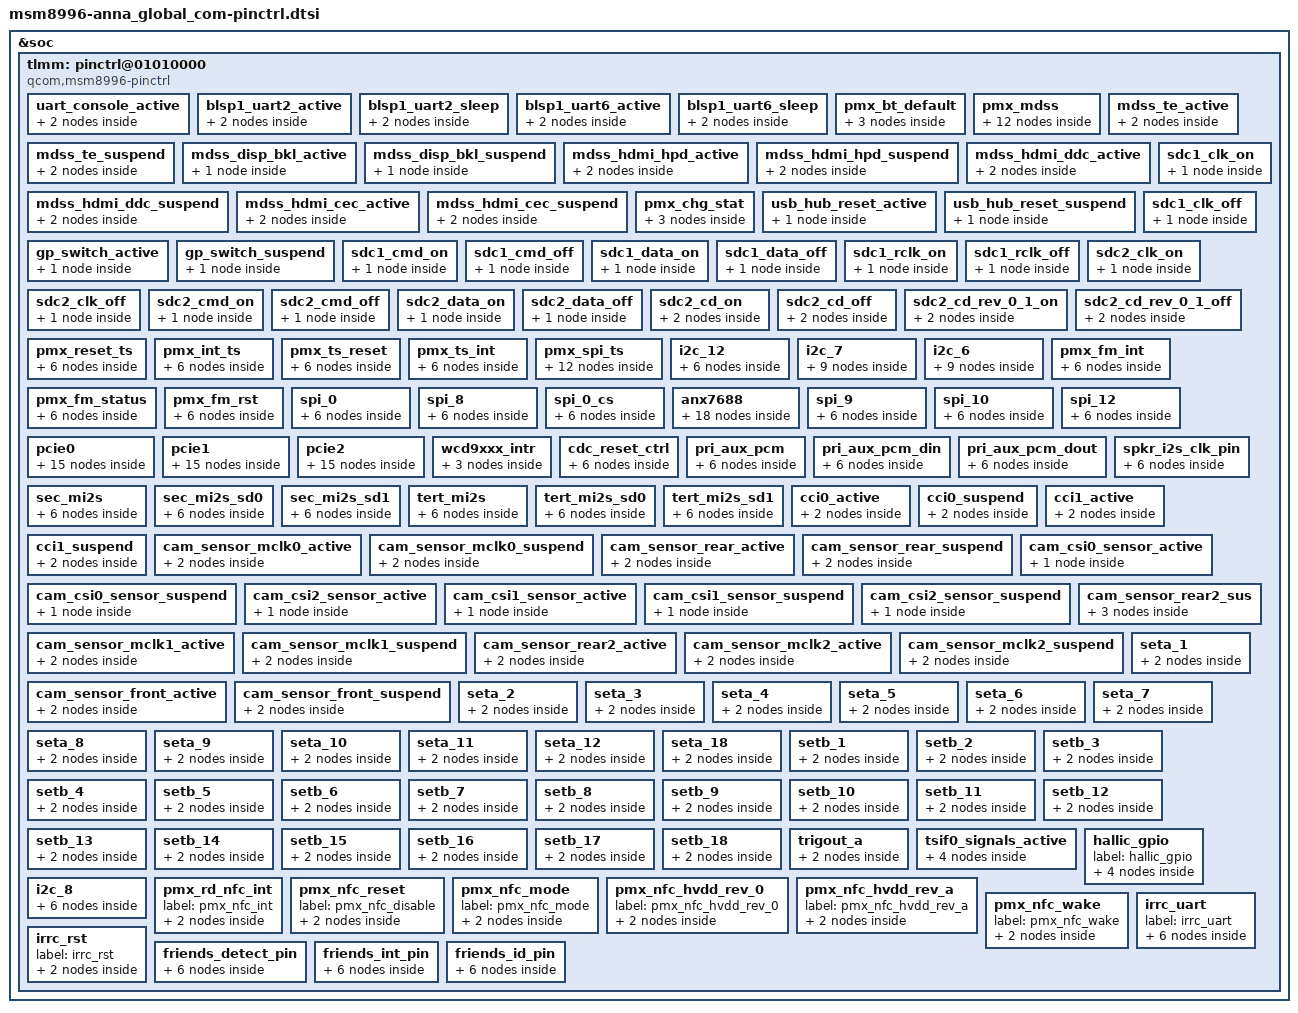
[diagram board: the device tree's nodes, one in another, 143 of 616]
/* Copyright (c) 2014-2015, The Linux Foundation. All rights reserved.
 *
 * This program is free software; you can redistribute it and/or modify
 * it under the terms of the GNU General Public License version 2 and
 * only version 2 as published by the Free Software Foundation.
 *
 * This program is distributed in the hope that it will be useful,
 * but WITHOUT ANY WARRANTY; without even the implied warranty of
 * MERCHANTABILITY or FITNESS FOR A PARTICULAR PURPOSE.  See the
 * GNU General Public License for more details.
 */

&soc {
	tlmm: pinctrl@01010000 {
		compatible = "qcom,msm8996-pinctrl";
		reg = <0x01010000 0x300000>;
		interrupts = <0 208 0>;
		gpio-controller;
		#gpio-cells = <2>;
		interrupt-controller;
		#interrupt-cells = <2>;

		uart_console_active: uart_console_active {
			mux {
				pins = "gpio4", "gpio5";
				function = "blsp_uart8";
			};

			config {
				pins = "gpio4", "gpio5";
				drive-strength = <6>;
				bias-disable;
			};
		};

		blsp1_uart2_active: blsp1_uart2_active {
			mux {
				pins = "gpio41", "gpio42", "gpio43", "gpio44";
				function = "blsp_uart2";
			};

			config {
				pins = "gpio41", "gpio42", "gpio43", "gpio44";
				drive-strength = <2>;
				bias-disable;
			};
		};

		blsp1_uart2_sleep: blsp1_uart2_sleep {
			mux {
				pins = "gpio41", "gpio42", "gpio43", "gpio44";
				function = "gpio";
			};

			config {
				pins = "gpio41", "gpio42", "gpio43", "gpio44";
				drive-strength = <2>;
				bias-disable;
			};
		};
//[ANNA_ISDBT_BRINGUP_S] : duplicated
/*
		blsp1_uart3_active: blsp1_uart3_active {
			mux {
				pins = "gpio45", "gpio46", "gpio47", "gpio48";
				function = "blsp_uart3";
			};

			config {
				pins = "gpio45", "gpio46", "gpio47", "gpio48";
				drive-strength = <2>;
				bias-disable;
			};
		};

		blsp1_uart3_sleep: blsp1_uart3_sleep {
			mux {
				pins = "gpio45", "gpio46", "gpio47", "gpio48";
				function = "gpio";
			};

			config {
				pins = "gpio45", "gpio46", "gpio47", "gpio48";
				drive-strength = <2>;
				bias-disable;
			};
		};
*/
//[ANNA_ISDBT_BRINGUP_E]
		blsp1_uart6_active: blsp1_uart6_active {
			mux {
				pins = "gpio25", "gpio26", "gpio27", "gpio28";
				function = "blsp_uart6";
			};

			config {
				pins = "gpio25", "gpio26", "gpio27", "gpio28";
				drive-strength = <2>;
				bias-disable;
			};
		};

		blsp1_uart6_sleep: blsp1_uart6_sleep {
			mux {
				pins = "gpio25", "gpio26", "gpio27", "gpio28";
				function = "gpio";
			};

			config {
				pins = "gpio25", "gpio26", "gpio27", "gpio28";
				drive-strength = <2>;
				bias-disable;
			};
		};

//[H1_BT_BRINGUP_S]
                /* gpio pin mux for bluetooth enable pin */
//[ANNA_ISDBT_BRINGUP_S] : duplicated
/*
		i2c_3 {
			i2c_3_active: i2c_3_active {
				mux {
					pins = "gpio47", "gpio48";
					function = "blsp_i2c3";
				};

				config {
					pins = "gpio47", "gpio48";
					drive-strength = <2>;
					bias-disable;
				};
			};

			i2c_3_sleep: i2c_3_sleep {
				mux {
					pins = "gpio47", "gpio48";
					function = "blsp_i2c3";
				};

				config {
					pins = "gpio47", "gpio48";
					drive-strength = <2>;
					bias-pull-up;
				};
			};
		};
*/		
//[ANNA_ISDBT_BRINGUP_E]
		/* gpio pin mux for bluetooth host wake pin */
                pmx_bt_default {
			bt_default: bt_default {
				mux {
					pins = "gpio24", "gpio92";
					function = "gpio";
				};

	    			config {
	    				pins = "gpio24", "gpio92";
	    				drive-strength = <2>;
	    				bias-disable = <0>;
	    			};
	                };
		};
//[H1_BT_BRINGUP_E]


		pmx_mdss: pmx_mdss {
			mdss_dsi_active: mdss_dsi_active {
				mux {
					pins = "gpio8";
					function = "gpio";
				};

				pmx_mdss {
					pins = "gpio8";
					drive-strength = <8>; /* 8 mA */
					bias-disable = <0>; /* no pull */
					output-high;
				};
			};
			mdss_dsi_suspend: mdss_dsi_suspend {
				mux {
					pins = "gpio8";
					function = "gpio";
				};

				config {
					pins = "gpio8";
					drive-strength = <2>; /* 2 mA */
					bias-pull-down; /* pull down */
				};
			};

			mdss_dsi_active3: mdss_dsi_active3 {
				mux {
					pins = "gpio121";
					function = "gpio";
				};

				pmx_mdss {
					pins = "gpio121";
					drive-strength = <2>; /* 2 mA */
					bias-pull-down;  /* pull down */
				};
			};
			mdss_dsi_suspend3: mdss_dsi_suspend3 {
				mux {
					pins = "gpio121";
					function = "gpio";
				};

				config {
					pins = "gpio121";
					drive-strength = <2>; /* 2 mA */
					bias-bus-hold;
				};
			};
		};

		mdss_te_active: mdss_te_active {
			mux {
				pins = "gpio10";
				function = "mdp_vsync";
			};
			config {
				pins = "gpio10";
				drive-strength = <2>; /* 8 mA */
				bias-pull-down; /* pull down*/
			};
		};


		mdss_te_suspend: mdss_te_suspend {
			mux {
				pins = "gpio10";
				function = "mdp_vsync";
			};
			config {
				pins = "gpio10";
				drive-strength = <2>; /* 2 mA */
				bias-pull-down; /* pull down */
			};
		};

		mdss_disp_bkl_active: mdss_disp_bkl_active {
			config {
				pins = "gpio135";
				drive-strength = <8>; /* 8 mA */
				bias-disable; /* no pull */
				output-high;
			};
		};

		mdss_disp_bkl_suspend: mdss_disp_bkl_suspend {
			config {
				pins = "gpio135";
				drive-strength = <2>; /* 2 mA */
				bias-pull-down; /* pull down */
			};
		};

		mdss_hdmi_hpd_active: mdss_hdmi_hpd_active {
			mux {
				pins = "gpio34";
				function = "hdmi_hot";
			};

			config {
				pins = "gpio34";
				bias-pull-down;
				drive-strength = <16>;
			};
		};

		mdss_hdmi_hpd_suspend: mdss_hdmi_hpd_suspend {
			mux {
				pins = "gpio34";
				function = "hdmi_hot";
			};

			config {
				pins = "gpio34";
				bias-bus-hold;
				drive-strength = <2>;
			};
		};

		mdss_hdmi_ddc_active: mdss_hdmi_ddc_active {
			mux {
				pins = "gpio32", "gpio33";
				function = "hdmi_ddc";
			};

			config {
				pins = "gpio32", "gpio33";
				drive-strength = <2>;
				bias-pull-up;
			};
		};

		mdss_hdmi_ddc_suspend: mdss_hdmi_ddc_suspend {
			mux {
				pins = "gpio32", "gpio33";
				function = "hdmi_ddc";
			};

			config {
				pins = "gpio32", "gpio33";
				drive-strength = <2>;
				bias-disable;
			};
		};

		mdss_hdmi_cec_active: mdss_hdmi_cec_active {
			mux {
				pins = "gpio31";
				function = "hdmi_cec";
			};

			config {
				pins = "gpio31";
				drive-strength = <2>;
				bias-pull-up;
			};
		};

		mdss_hdmi_cec_suspend: mdss_hdmi_cec_suspend {
			mux {
				pins = "gpio31";
				function = "hdmi_cec";
			};

			config {
				pins = "gpio31";
				drive-strength = <2>;
				bias-disable;
			};
		};

		/* gpio pin mux for back-up battery charging status pin */
		pmx_chg_stat {
			chg_stat_active: chg_stat_active {
				mux {
					pins = "gpio45";
					function = "gpio";
				};
				config {
					pins = "gpio45";
					drive-strength = <2>;
					bias-pull-up;
				};
			};
		};

		usb_hub_reset_active: usb_hub_reset_active {
			usb_hub_reset_active {
				pins = "gpio103";
				drive-strength = <8>; /* 8 mA */
				bias-pull-up;  /* pull up */
				output-high;
			};
		};

		usb_hub_reset_suspend: usb_hub_reset_suspend {
			usb_hub_reset_suspend {
				pins = "gpio103";
				drive-strength = <2>; /* 2 mA */
				bias-disable= <0>; /* no pull */
			};
		};


		gp_switch_active: gp_switch_active {
			gp_switch_active {
				pins = "gpio127";
				drive-strength = <8>; /* 8 mA */
				bias-pull-up;  /* pull up */
				output-low;
			};
		};

		gp_switch_suspend: gp_switch_suspend {
			gp_switch_suspend {
				pins = "gpio127";
				drive-strength = <2>; /* 2 mA */
				bias-disable= <0>; /* no pull */
			};
		};


		sdc1_clk_on: sdc1_clk_on {
			config {
				pins = "sdc1_clk";
				bias-disable;		/* NO pull */
				drive-strength = <16>;	/* 16 MA */
			};
		};

		sdc1_clk_off: sdc1_clk_off {
			config {
				pins = "sdc1_clk";
				bias-disable;		/* NO pull */
				drive-strength = <2>;	/* 2 MA */
			};
		};

		sdc1_cmd_on: sdc1_cmd_on {
			config {
				pins = "sdc1_cmd";
				bias-pull-up;		/* pull up */
				drive-strength = <10>;	/* 10 MA */
			};
		};

		sdc1_cmd_off: sdc1_cmd_off {
			config {
				pins = "sdc1_cmd";
				num-grp-pins = <1>;
				bias-pull-up;		/* pull up */
				drive-strength = <2>;	/* 2 MA */
			};
		};

		sdc1_data_on: sdc1_data_on {
			config {
				pins = "sdc1_data";
				bias-pull-up;		/* pull up */
				drive-strength = <10>;	/* 10 MA */
			};
		};

		sdc1_data_off: sdc1_data_off {
			config {
				pins = "sdc1_data";
				bias-pull-up;		/* pull up */
				drive-strength = <2>;	/* 2 MA */
			};
		};

		sdc1_rclk_on: sdc1_rclk_on {
			config {
				pins = "sdc1_rclk";
				bias-pull-down;		/* pull down */
			};
		};

		sdc1_rclk_off: sdc1_rclk_off {
			config {
				pins = "sdc1_rclk";
				bias-pull-down;		/* pull down */
			};
		};

		sdc2_clk_on: sdc2_clk_on {
			config {
				pins = "sdc2_clk";
				bias-disable;		/* NO pull */
				drive-strength = <16>;	/* 16 MA */
			};
		};

		sdc2_clk_off: sdc2_clk_off {
			config {
				pins = "sdc2_clk";
				bias-disable;		/* NO pull */
				drive-strength = <2>;	/* 2 MA */
			};
		};

		sdc2_cmd_on: sdc2_cmd_on {
			config {
				pins = "sdc2_cmd";
				bias-pull-up;		/* pull up */
				drive-strength = <10>;	/* 10 MA */
			};
		};

		sdc2_cmd_off: sdc2_cmd_off {
			config {
				pins = "sdc2_cmd";
				bias-pull-up;		/* pull up */
				drive-strength = <2>;	/* 2 MA */
			};
		};

		sdc2_data_on: sdc2_data_on {
			config {
				pins = "sdc2_data";
				bias-pull-up;		/* pull up */
				drive-strength = <10>;	/* 10 MA */
			};
		};

		sdc2_data_off: sdc2_data_off {
			config {
				pins = "sdc2_data";
				bias-pull-up;		/* pull up */
				drive-strength = <2>;	/* 2 MA */
			};
		};

		sdc2_cd_on: sdc2_cd_on {
			mux {
				pins = "gpio79";
				function = "gpio";
			};

			config {
				pins = "gpio79";
				bias-pull-up;		/* pull up */
				drive-strength = <16>;	/* 16 MA */
			};
		};

		sdc2_cd_off: sdc2_cd_off {
			mux {
				pins = "gpio79";
				function = "gpio";
			};

			config {
				pins = "gpio79";
				bias-disable;		/* no pull */
				drive-strength = <2>;	/* 2 MA */
			};
		};

        sdc2_cd_rev_0_1_on: sdc2_cd_rev_0_1_on {
            mux {
                pins = "gpio112";
                function = "gpio";
            };

            config {
                pins = "gpio112";
                bias-pull-up;
                drive_strength = <16>;
            };
        };

        sdc2_cd_rev_0_1_off: sdc2_cd_rev_0_1_off {
            mux {
                pins = "gpio112";
                function = "gpio";
            };

            config {
                pins = "gpio112";
                bias-pull-up;
                drive_strength = <2>;
            };
        };

		pmx_reset_ts {
			reset_active_ts: reset_active_ts {
				mux {
					pins = "gpio89";
					function = "gpio";
				};
				config {
					pins = "gpio89";
					drive-strength = <6>;
					bias-pull-up;
				};
			};

			reset_suspend_ts: reset_suspend_ts {
				mux {
					pins = "gpio89";
					function = "gpio";
				};
				config {
					pins = "gpio89";
					drive-strength = <6>;
					bias-pull-down;
				};
			};
		};

		pmx_int_ts {
			int_active_ts: int_active_ts {
				mux {
					pins = "gpio125";
					function = "gpio";
				};
				config {
					pins = "gpio125";
					drive-strength = <2>;
					bias-disable;
				};
			};

			int_suspend_ts: int_suspend_ts {
				mux {
					pins = "gpio125";
					function = "gpio";
				};
				config {
					pins = "gpio125";
					drive-strength = <2>;
					bias-disable;
				};
			};
		};

		pmx_ts_reset {
			ts_reset_active: ts_reset_active {
				mux {
					pins = "gpio89";
					function = "gpio";
				};
				config {
					pins = "gpio89";
					drive-strength = <6>;
					bias-pull-up;
				};
			};

			ts_reset_suspend: ts_reset_suspend {
				mux {
					pins = "gpio89";
					function = "gpio";
				};
				config {
					pins = "gpio89";
					drive-strength = <6>;
					bias-pull-down;
				};
			};
		};

		pmx_ts_int {
			ts_int_active: ts_int_active {
				mux {
					pins = "gpio125";
					function = "gpio";
				};
				config {
					pins = "gpio125";
					drive-strength = <2>;
					bias-pull-up;
				};
			};

			ts_int_suspend: ts_int_suspend {
				mux {
					pins = "gpio125";
					function = "gpio";
				};
				config {
					pins = "gpio125";
					drive-strength = <2>;
					bias-disable;
				};
			};
		};

		pmx_spi_ts: pmx_spi_ts {
			spi_ts_active: spi_ts_active {
			/* TOUCH MOSI, MISO */
				mux {
					pins = "gpio85", "gpio86";
					function = "blsp_spi12";
				};
				config {
					pins = "gpio85", "gpio86";
					drive-strength = <8>; /* 8MA */
					bias-pull-up;
				};
			};

			spi_ts_suspend: spi_ts_suspend {
			/* TOUCH MOSI, MISO */
				mux {
					pins = "gpio85", "gpio86";
					function = "blsp_spi12";
				};
				config {
					pins = "gpio85", "gpio86";
					drive-strength = <2>; /* 2MA */
					bias-disable; /* No PULL */
				};
			};

			spi_ts_cs_active: spi_ts_cs_active {
				mux {
					pins = "gpio87", "gpio88";
					function = "blsp_spi12";
				};
				config {
					pins = "gpio87", "gpio88";
					drive-strength = <8>;
					bias-pull-up;
				};
			};

			spi_ts_cs_suspend: spi_ts_cs_suspend {
				mux {
					pins = "gpio87", "gpio88";
					function = "blsp_spi12";
				};
				config {
					pins = "gpio87", "gpio88";
					drive-strength = <2>;
					bias-disable; /* No PULL */
				};
			};
		};

		i2c_12 {
			i2c_12_active: i2c_12_active {
				mux {
					pins = "gpio87", "gpio88";
					function = "blsp_i2c12";
				};

				config {
					pins = "gpio87", "gpio88";
					drive-strength = <2>;
					bias-disable;
				};
			};

			i2c_12_sleep: i2c_12_sleep {
				mux {
					pins = "gpio87", "gpio88";
					function = "blsp_i2c12";
				};

				config {
					pins = "gpio87", "gpio88";
					drive-strength = <2>;
					bias-pull-up;
				};
			};

		};

		i2c_7 {
			i2c_7_default: i2c_7_default {
				mux {
					pins = "gpio55", "gpio56";
					function = "blsp_i2c7";
				};

				config {
					pins = "gpio55", "gpio56";
					drive-strength = <2>;
					bias-disable;
				};
			};

			i2c_7_active: i2c_7_active {
				mux {
					pins = "gpio55", "gpio56";
					function = "blsp_i2c7";
				};

				config {
					pins = "gpio55", "gpio56";
					drive-strength = <2>;
					bias-disable;
				};
			};

			i2c_7_sleep: i2c_7_sleep {
				mux {
					pins = "gpio55", "gpio56";
					function = "blsp_i2c7";
				};

				config {
					pins = "gpio55", "gpio56";
					drive-strength = <2>;
					bias-pull-up;
				};
			};

		};

		i2c_6 {
			i2c_6_default: i2c_6_default {
				mux {
					pins = "gpio27", "gpio28";
					function = "blsp_i2c6";
				};

				config {
					pins = "gpio27", "gpio28";
					drive-strength = <2>;
					bias-disable;
				};
			};

			i2c_6_active: i2c_6_active {
				mux {
					pins = "gpio27", "gpio28";
					function = "blsp_i2c6";
				};

				config {
					pins = "gpio27", "gpio28";
					drive-strength = <2>;
					bias-disable;
				};
			};


			i2c_6_sleep: i2c_6_sleep {
				mux {
					pins = "gpio27", "gpio28";
					function = "blsp_i2c6";
				};

				config {
					pins = "gpio27", "gpio28";
					drive-strength = <2>;
					bias-pull-up;
				};
			};

		};

		pmx_fm_int {
			fm_int_active: fm_int_active {
				mux {
					pins = "gpio38";
					function = "gpio";
				};

				config {
					pins = "gpio38";
					drive-strength = <16>;
					bias-pull-up;
				};
			};

		fm_int_suspend: fm_int_suspend {
				mux {
					pins = "gpio38";
					function = "gpio";
				};

				config {
					pins = "gpio38";
					drive-strength = <16>;
					bias-pull-up;
				};
			};
		};

		pmx_fm_status {
			fm_status_int_active: fm_status_int_active {
				mux {
					pins = "gpio78";
					function = "gpio";
				};

				config {
					pins = "gpio78";
					drive-strength = <16>;
					bias-pull-up;
				};
			};

			fm_status_int_suspend: fm_status_int_suspend {
				mux {
					pins = "gpio78";
					function = "gpio";
				};

				config {
					pins = "gpio78";
					drive-strength = <16>;
					bias-pull-up;
				};
			};
		};

		pmx_fm_rst {
			fm_rst_active: fm_rst_active {
				mux {
					pins = "gpio39";
					function = "gpio";
				};

				config {
					pins = "gpio39";
					drive-strength = <16>;
					bias-pull-down;
				};
			};

			fm_rst_suspend: fm_rst_suspend {
				mux {
					pins = "gpio39";
					function = "gpio";
				};

				config {
					pins = "gpio39";
					drive-strength = <16>;
					bias-pull-down;
				};
			};
		};

		spi_0 {
			spi_0_active: spi_0_active {
				mux {
					pins = "gpio0", "gpio1",
						"gpio2", "gpio3";
					function = "blsp_spi1";
				};

				config {
					pins = "gpio0", "gpio1",
						"gpio2", "gpio3";
					drive-strength = <6>;
					bias-disable;
				};
			};

			spi_0_sleep: spi_0_sleep {
				mux {
					pins = "gpio0", "gpio1",
						"gpio2", "gpio3";
					function = "blsp_spi1";
				};

				config {
					pins = "gpio0", "gpio1",
						"gpio2", "gpio3";
					drive-strength = <6>;
					bias-disable;
				};
			};
		};

		spi_8 {
			spi_8_active: spi_8_active {
				mux {
					pins = "gpio49", "gpio50",
					        "gpio51", "gpio52";
					function = "blsp_spi9";
				};

				config {
					pins = "gpio49", "gpio50",
					        "gpio51", "gpio52";
					drive-strength = <6>;
					bias-disable;
				};
			};

			spi_8_sleep: spi_8_sleep {
				mux {
					pins = "gpio49", "gpio50",
						"gpio51", "gpio52";
					function = "blsp_spi9";
				};

				config {
					pins = "gpio49", "gpio50",
						"gpio51", "gpio52";
					drive-strength = <6>;
					bias-disable;
				};
			};
		};

		spi_0_cs {
			spi_0_cs_active: spi_0_cs_active {
				mux {
					pins = "gpio24", "gpio90";
					function = "blsp1_spi";
				};

				config {
					pins = "gpio24", "gpio90";
					drive-strength = <6>;
					bias-pull-up;
				};
			};

			spi_0_cs_sleep: spi_0_cs_sleep {
				mux {
					pins = "gpio24", "gpio90";
					function = "blsp1_spi";
				};

				config {
					pins = "gpio24", "gpio90";
					drive-strength = <6>;
					bias-pull-up;
				};
			};
		};

		anx7688 {
			anx7688_cable_det_active: anx7688_cable_det_active {
				mux {
					pins = "gpio131";
					function = "gpio";
				};

				config {
					pins = "gpio131";
					driver-strength = <8>;
					bias-bus-hold;
				};
			};

			anx7688_cable_det_sleep: anx7688_cable_det_sleep {
				mux {
					pins = "gpio131";
					function = "gpio";
				};

				config {
					pins = "gpio131";
					driver-strength = <2>;
					bias-bus-hold;
				};
			};

			anx7688_alt_active: anx7688_alt_active {
				mux {
					pins = "gpio46";
					function = "gpio";
				};

				config {
					pins = "gpio46";
					driver-strength = <8>;
					bias-pull-up;
				};
			};

			anx7688_alt_sleep: anx7688_alt_sleep {
				mux {
					pins = "gpio46";
					function = "gpio";
				};

				config {
					pins = "gpio46";
					driver-strength = <2>;
					bias-pull-up;
				};
			};
                        anx7688_hpd_active: anx7688_hpd_active {
                                mux {
                                        pins = "gpio34";
                                        function = "gpio";
                                };

                                config {
                                        pins = "gpio34";
                                        driver-strength = <8>;
                                        bias-disable;
                                };
                        };

                        anx7688_hpd_sleep: anx7688_hpd_sleep {
                                mux {
                                        pins = "gpio34";
                                        function = "gpio";
                                };

                                config {
                                        pins = "gpio34";
                                        driver-strength = <8>;
                                        bias-disable;
                                };
                        };

		};

		spi_9 {
			spi_9_active: spi_9_active {
				mux {
					pins = "gpio49", "gpio50", "gpio51",
								"gpio52";
					function = "blsp_spi9";
				};

				config {
					pins = "gpio49", "gpio50", "gpio51",
								"gpio52";
					drive-strength = <6>;
					bias-disable;
				};
			};

			spi_9_sleep: spi_9_sleep {
				mux {
					pins = "gpio49", "gpio50", "gpio51",
								"gpio52";
					function = "blsp_spi9";
				};

				config {
					pins = "gpio49", "gpio50", "gpio51",
								"gpio52";
					drive-strength = <6>;
					bias-disable;
				};
			};
		};

		spi_10 {
			spi_10_active: spi_10_active {
				mux {
					pins = "gpio8", "gpio9", "gpio10",
								"gpio11";
					function = "blsp_spi10";
				};

				config {
					pins = "gpio8", "gpio9", "gpio10",
								"gpio11";
					drive-strength = <6>;
					bias-disable;
				};
			};

			spi_10_sleep: spi_10_sleep {
				mux {
					pins = "gpio8", "gpio9", "gpio10",
								"gpio11";
					function = "blsp_spi10";
				};

				config {
					pins = "gpio8", "gpio9", "gpio10",
								"gpio11";
					drive-strength = <6>;
					bias-disable;
				};
			};
		};

		spi_12 {
			spi_12_active: spi_12_active {
				mux {
					pins = "gpio85", "gpio86", "gpio87",
								"gpio88";
					function = "blsp_spi12";
				};

				config {
					pins = "gpio85", "gpio86", "gpio87",
								"gpio88";
					drive-strength = <6>;
					bias-disable;
				};
			};

			spi_12_sleep: spi_12_sleep {
				mux {
					pins = "gpio85", "gpio86", "gpio87",
								"gpio88";
					function = "blsp_spi12";
				};

				config {
					pins = "gpio85", "gpio86", "gpio87",
								"gpio88";
					drive-strength = <6>;
					bias-disable;
				};
			};
		};

		pcie0 {
			pcie0_clkreq_default: pcie0_clkreq_default {
				mux {
					pins = "gpio36";
					function = "pci_e0";
				};

				config {
					pins = "gpio36";
					drive-strength = <2>;
					bias-pull-up;
				};
			};

			pcie0_perst_default: pcie0_perst_default {
				mux {
					pins = "gpio35";
					function = "gpio";
				};

				config {
					pins = "gpio35";
					drive-strength = <2>;
					bias-pull-down;
				};
			};

			pcie0_wake_default: pcie0_wake_default {
				mux {
					pins = "gpio37";
					function = "gpio";
				};

				config {
					pins = "gpio37";
					drive-strength = <2>;
					bias-pull-up;
				};
			};

			pcie0_clkreq_sleep: pcie0_clkreq_sleep {
				mux {
					pins = "gpio36";
					function = "gpio";
				};

				config {
					pins = "gpio36";
					drive-strength = <2>;
					bias-disable;
				};
			};

			pcie0_wake_sleep: pcie0_wake_sleep {
				mux {
					pins = "gpio37";
					function = "gpio";
				};

				config {
					pins = "gpio37";
					drive-strength = <2>;
					bias-disable;
				};
			};
		};

		pcie1 {
			pcie1_clkreq_default: pcie1_clkreq_default {
				mux {
					pins = "gpio131";
					function = "pci_e0";
				};

				config {
					pins = "gpio131";
					drive-strength = <2>;
					bias-pull-up;
				};
			};

			pcie1_perst_default: pcie1_perst_default {
				mux {
					pins = "gpio130";
					function = "gpio";
				};

				config {
					pins = "gpio130";
					drive-strength = <2>;
					bias-pull-down;
				};
			};

			pcie1_wake_default: pcie1_wake_default {
				mux {
					pins = "gpio132";
					function = "gpio";
				};

				config {
					pins = "gpio132";
					drive-strength = <2>;
					bias-pull-up;
				};
			};

			pcie1_clkreq_sleep: pcie1_clkreq_sleep {
				mux {
					pins = "gpio131";
					function = "gpio";
				};

				config {
					pins = "gpio131";
					drive-strength = <2>;
					bias-disable;
				};
			};

			pcie1_wake_sleep: pcie1_wake_sleep {
				mux {
					pins = "gpio132";
					function = "gpio";
				};

				config {
					pins = "gpio132";
					drive-strength = <2>;
					bias-disable;
				};
			};
		};

		pcie2 {
			pcie2_clkreq_default: pcie2_clkreq_default {
				mux {
					pins = "gpio115";
					function = "pci_e2";
				};

				config {
					pins = "gpio115";
					drive-strength = <2>;
					bias-pull-up;
				};
			};

			pcie2_perst_default: pcie2_perst_default {
				mux {
					pins = "gpio114";
					function = "gpio";
				};

				config {
					pins = "gpio114";
					drive-strength = <2>;
					bias-pull-down;
				};
			};

			pcie2_wake_default: pcie2_wake_default {
				mux {
					pins = "gpio116";
					function = "gpio";
				};

				config {
					pins = "gpio116";
					drive-strength = <2>;
					bias-pull-down;
				};
			};

			pcie2_clkreq_sleep: pcie2_clkreq_sleep {
				mux {
					pins = "gpio115";
					function = "gpio";
				};

				config {
					pins = "gpio115";
					drive-strength = <2>;
					bias-disable;
				};
			};

			pcie2_wake_sleep: pcie2_wake_sleep {
				mux {
					pins = "gpio116";
					function = "gpio";
				};

				config {
					pins = "gpio116";
					drive-strength = <2>;
					bias-disable;
				};
			};
		};

		wcd9xxx_intr {
			wcd_intr_default: wcd_intr_default{
				mux {
					pins = "gpio54";
					function = "gpio";
				};

				config {
					pins = "gpio54";
					drive-strength = <2>; /* 2 mA */
					bias-pull-down; /* pull down */
					input-enable;
				};
			};
		};

		cdc_reset_ctrl {
			cdc_reset_sleep: cdc_reset_sleep {
				mux {
					pins = "gpio64";
					function = "gpio";
				};
				config {
					pins = "gpio64";
					drive-strength = <16>;
					bias-disable;
					output-low;
				};
			};
			cdc_reset_active:cdc_reset_active {
				mux {
					pins = "gpio64";
					function = "gpio";
				};
				config {
					pins = "gpio64";
					drive-strength = <16>;
					bias-pull-down;
					output-high;
				};
			};
		};

		pri_aux_pcm {
			pri_aux_pcm_sleep: pri_aux_pcm_sleep {
				mux {
					pins = "gpio65", "gpio66", "gpio67";
					function = "pri_mi2s";
				};

				config {
					pins = "gpio65", "gpio66", "gpio67";
					drive-strength = <2>;   /* 2 mA */
					bias-pull-down;         /* PULL DOWN */
				};
			};
			pri_aux_pcm_active: pri_aux_pcm_active {
				mux {
					pins = "gpio65", "gpio66", "gpio67";
					function = "pri_mi2s";
				};

				config {
					pins = "gpio65", "gpio66", "gpio67";
					drive-strength = <8>;   /* 8 mA */
					bias-disable;           /* NO PULL */
					output-high;
				};
			};
		};

		pri_aux_pcm_din {
			pri_aux_pcm_din_sleep: pri_aux_pcm_din_sleep {
				mux {
					pins = "gpio68";
					function = "pri_mi2s";
				};

				config {
					pins = "gpio68";
					drive-strength = <2>;   /* 2 mA */
					bias-pull-down;         /* PULL DOWN */
				};
			};
			pri_aux_pcm_din_active: pri_aux_pcm_din_active {
				mux {
					pins = "gpio68";
					function = "pri_mi2s";
				};

				config {
					pins = "gpio68";
					drive-strength = <8>;   /* 8 mA */
					bias-disable;           /* NO PULL */
				};
			};
		};

		pri_aux_pcm_dout {
			pri_aux_pcm_dout_sleep: pri_aux_pcm_dout_sleep {
				mux {
					pins = "gpio68";
					function = "pri_mi2s";
				};

				config {
					pins = "gpio68";
					drive-strength = <2>;   /* 2 mA */
					bias-pull-down;         /* PULL DOWN */
				};
			};
			pri_aux_pcm_dout_active: pri_aux_pcm_dout_active {
				mux {
					pins = "gpio68";
					function = "pri_mi2s";
				};

				config {
					pins = "gpio68";
					drive-strength = <8>;   /* 8 mA */
					bias-disable;           /* NO PULL */
				};
			};
		};

		spkr_i2s_clk_pin {
			spkr_i2s_clk_sleep: spkr_i2s_clk_sleep {
				mux {
					pins = "gpio143";
					function = "spkr_i2s";
				};

				config {
					pins = "gpio143";
					drive-strength = <2>; /* 2 mA */
					bias-pull-down;       /* PULL DOWN */
				};
			};
			spkr_i2s_clk_active: spkr_i2s_clk_active {
				mux {
					pins = "gpio143";
					function = "spkr_i2s";
				};

				config {
					pins = "gpio143";
					drive-strength = <8>; /* 8 mA */
					bias-disable;         /* NO PULL */
				};
			};
		};

    	sec_mi2s {
			sec_mi2s_sleep: sec_mi2s_sleep {
				mux {
					pins = "gpio80", "gpio81";
					function = "sec_mi2s";
				};
				config {
					pins = "gpio80", "gpio81";
					drive-strength = <2>;   /* 2 mA */
					bias-pull-down;         /* PULL DOWN */
				};
			};
			sec_mi2s_active: sec_mi2s_active {
				mux {
					pins = "gpio80", "gpio81";
					function = "sec_mi2s";
				};
				config {
					pins = "gpio80", "gpio81";
					drive-strength = <8>;   /* 8 mA */
					bias-disable;           /* NO PULL */
				};
			};
		};
        
		sec_mi2s_sd0 {
			sec_mi2s_sd0_sleep: sec_mi2s_sd0_sleep {
				mux {
					pins = "gpio82";
					function = "sec_mi2s";
				};
				config {
					pins = "gpio82";
					drive-strength = <2>;   /* 2 mA */
					bias-pull-down;         /* PULL DOWN */
				};
			};
			sec_mi2s_sd0_active: sec_mi2s_sd0_active {
				mux {
					pins = "gpio82";
					function = "sec_mi2s";
				};
				config {
					pins = "gpio82";
					drive-strength = <8>;   /* 8 mA */
					bias-disable;           /* NO PULL */
				};
			};
		};

		sec_mi2s_sd1 {
			sec_mi2s_sd1_sleep: sec_mi2s_sd1_sleep {
				mux {
					pins = "gpio83";
					function = "sec_mi2s";
				};
				config {
					pins = "gpio83";
					drive-strength = <2>;   /* 2 mA */
					bias-pull-down;         /* PULL DOWN */
				};
			};
			sec_mi2s_sd1_active: sec_mi2s_sd1_active {
				mux {
					pins = "gpio83";
					function = "sec_mi2s";
				};
				config {
					pins = "gpio83";
					drive-strength = <8>;   /* 8 mA */
					bias-disable;           /* NO PULL */
				};
			};
		};

		tert_mi2s{
			tert_mi2s_sleep: tert_mi2s_sleep{
				mux {
					pins = "gpio75", "gpio76";
					function = "ter_mi2s";
				};
				config {
					pins = "gpio75", "gpio76";
					drive-strength = <2>;   /* 2 mA */
					bias-pull-down;         /* PULL DOWN */
				};
			};
			tert_mi2s_active: tert_mi2s_active{
				mux {
					pins = "gpio75", "gpio76";
					function = "ter_mi2s";
				};
				config {
					pins = "gpio75", "gpio76";
					drive-strength = <8>;   /* 8 mA */
					bias-disable;           /* NO PULL */
				};
			};
		};

		tert_mi2s_sd0 {
			tert_mi2s_sd0_sleep: tert_mi2s_sd0_sleep {
				mux {
					pins = "gpio77";
					function = "ter_mi2s";
				};
				config {
					pins = "gpio77";
					drive-strength = <2>;   /* 2 mA */
					bias-pull-down;         /* PULL DOWN */
				};
			};
			tert_mi2s_sd0_active: tert_mi2s_sd0_active {
				mux {
					pins = "gpio77";
					function = "ter_mi2s";
				};
				config {
					pins = "gpio77";
					drive-strength = <8>;   /* 8 mA */
					bias-disable;           /* NO PULL */
				};
			};
		};

		tert_mi2s_sd1 {
			tert_mi2s_sd1_sleep: tert_mi2s_sd1_sleep {
				mux {
					pins = "gpio78";
					function = "ter_mi2s";
				};
				config {
					pins = "gpio78";
					drive-strength = <2>;   /* 2 mA */
					bias-pull-down;         /* PULL DOWN */
				};
			};
			tert_mi2s_sd1_active: tert_mi2s_sd1_active {
				mux {
					pins = "gpio78";
					function = "ter_mi2s";
				};
				config {
					pins = "gpio78";
					drive-strength = <8>;   /* 8 mA */
					bias-disable;           /* NO PULL */
				};
			};
		};

		cci0_active: cci0_active {
			mux {
				/* CLK, DATA */
				pins = "gpio17","gpio18"; // Only 2
				function = "cci_i2c";
			};

			config {
				pins = "gpio17","gpio18";
				bias-disable; /* No PULL */
				drive-strength = <2>; /* 2 MA */
			};
		};

		cci0_suspend: cci0_suspend {
			mux {
				/* CLK, DATA */
				pins = "gpio17","gpio18";
				function = "cci_i2c";
			};

			config {
				pins = "gpio17","gpio18";
				bias-disable; /* No PULL */
				drive-strength = <2>; /* 2 MA */
			};
		};

		cci1_active: cci1_active {
			mux {
				/* CLK, DATA */
				pins = "gpio19","gpio20";
				function = "cci_i2c";
			};

			config {
				pins = "gpio19","gpio20";
				bias-disable; /* No PULL */
				drive-strength = <2>; /* 2 MA */
			};
		};

		cci1_suspend: cci1_suspend {
			mux {
				/* CLK, DATA */
				pins = "gpio19","gpio20";
				function = "cci_i2c";
			};

			config {
				pins = "gpio19","gpio20";
				bias-disable; /* No PULL */
				drive-strength = <2>; /* 2 MA */
			};
		};

		cam_sensor_mclk0_active: cam_sensor_mclk0_active {
			/* MCLK0 */
			mux {
				/* CLK, DATA */
				pins = "gpio13";
				function = "cam_mclk";
			};

			config {
				pins = "gpio13";
				bias-disable; /* No PULL */
				drive-strength = <2>; /* 2 MA */
			};
		};

		cam_sensor_mclk0_suspend: cam_sensor_mclk0_suspend {
			/* MCLK0 */
			mux {
				/* CLK, DATA */
				pins = "gpio13";
				function = "cam_mclk";
			};

			config {
				pins = "gpio13";
				bias-pull-down; /* PULL DOWN */
				drive-strength = <2>; /* 2 MA */
			};
		};

		cam_sensor_rear_active: cam_sensor_rear_active {
			/* RESET, STANDBY */
			mux {
				pins = "gpio30";
				function = "gpio";
			};

			config {
				pins = "gpio30"; //,"gpio29";
				bias-disable; /* No PULL */
				drive-strength = <2>; /* 2 MA */
			};
		};

		cam_sensor_rear_suspend: cam_sensor_rear_suspend{
			/* RESET, STANDBY */
			mux {
				pins = "gpio30"; //,"gpio29";
				function = "gpio";
			};

			config {
				pins = "gpio30"; //,"gpio29";
				bias-disable; /* No PULL */
				drive-strength = <2>; /* 2 MA */
			};
		};

		cam_csi0_sensor_active: cam_csi0_sensor_active {
			/* RESET, STANDBY */
			cam_rear_active_cfg {
				pins = "gpio25","gpio26";
				bias-disable; /* No PULL */
				drive-strength = <2>; /* 2 MA */
			};
		};

		cam_csi0_sensor_suspend: cam_csi0_sensor_suspend{
			/* RESET, STANDBY */
			cam_rear_suspend_cfg {
				pins = "gpio25","gpio26";
				bias-disable; /* No PULL */
				drive-strength = <2>; /* 2 MA */
			};
		};

		cam_csi2_sensor_active: cam_csi2_sensor_active {
			/* RESET, STANDBY */
			cam_rear_active_cfg {
				pins = "gpio23","gpio133";
				bias-disable; /* No PULL */
				drive-strength = <2>; /* 2 MA */
			};
		};

		cam_csi1_sensor_active: cam_csi1_sensor_active {
			/* RESET, STANDBY */
			cam_rear_active_cfg {
				pins = "gpio104","gpio98";
				bias-disable; /* No PULL */
				drive-strength = <2>; /* 2 MA */
			};
		};

		cam_csi1_sensor_suspend: cam_csi1_sensor_suspend {
			/* RESET, STANDBY */
			cam_rear_suspend_cfg {
				pins = "gpio104","gpio98";
				bias-disable; /* No PULL */
				drive-strength = <2>; /* 2 MA */
			};
		};

		cam_csi2_sensor_suspend: cam_csi2_sensor_suspend{
			/* RESET, STANDBY */
			cam_rear_suspend_cfg {
				pins = "gpio23","gpio133";
				bias-disable; /* No PULL */
				drive-strength = <2>; /* 2 MA */
			};
		};

		cam_sensor_mclk1_active: cam_sensor_mclk1_active{
			/* MCLK1 */
			mux {
				/* CLK, DATA */
				pins = "gpio14";
				function = "cam_mclk";
			};

			config {
				pins = "gpio14";
				bias-disable; /* No PULL */
				drive-strength = <2>; /* 2 MA */
			};
		};

		cam_sensor_mclk1_suspend: cam_sensor_mclk1_suspend {
			/* MCLK1 */
			mux {
				/* CLK, DATA */
				pins = "gpio14";
				function = "cam_mclk";
			};

			config {
				pins = "gpio14";
				bias-pull-down; /* PULL DOWN */
				drive-strength = <2>; /* 2 MA */
			};
		};

		cam_sensor_rear2_active: cam_sensor_rear2_active {
			/* RESET, STANDBY */
			mux {
				pins = "gpio29"; //"gpio63","gpio62";
				function = "gpio";
			};

			config {
				pins = "gpio29"; //"gpio63","gpio62";
				bias-disable; /* No PULL */
				drive-strength = <2>; /* 2 MA */
			};
		};

		cam_sensor_rear2_sus {
			cam_sensor_rear2_suspend: cam_sensor_rear2_suspend{
				/* RESET, STANDBY */
				mux {
					pins = "gpio29"; //"gpio63","gpio62";
					function = "gpio";
				};

				config {
					pins = "gpio29"; //"gpio63","gpio62";
					bias-disable; /* No PULL */
					drive-strength = <2>; /* 2 MA */
				};
			};
		};

		cam_sensor_mclk2_active: cam_sensor_mclk2_active {
			/* MCLK1 */
			mux {
				/* CLK, DATA */
				pins = "gpio15";
				function = "cam_mclk";
			};

			config {
				pins = "gpio15";
				bias-disable; /* No PULL */
				drive-strength = <2>; /* 2 MA */
			};
		};

		cam_sensor_mclk2_suspend: cam_sensor_mclk2_suspend{
			/* MCLK1 */
			mux {
				/* CLK, DATA */
				pins = "gpio15";
				function = "cam_mclk";
			};

			config {
				pins = "gpio15";
				bias-pull-down; /* PULL DOWN */
				drive-strength = <2>; /* 2 MA */
			};
		};

		cam_sensor_front_active: cam_sensor_front_active{
			/* RESET, STANDBY */
			mux {
				pins = "gpio23";//,"gpio26";
				function = "gpio";
			};

			config {
				pins = "gpio23";//,"gpio26";
				bias-disable; /* No PULL */
				drive-strength = <2>; /* 2 MA */
			};
		};

		cam_sensor_front_suspend: cam_sensor_front_suspend{
			/* RESET, STANDBY */
			mux {
				pins = "gpio23";//,"gpio26";
				function = "gpio";
			};

			config {
				pins = "gpio23";//,"gpio26";
				bias-disable; /* No PULL */
				drive-strength = <2>; /* 2 MA */
			};
		};

		/* CoreSight */
		seta_1: seta_1 {
			mux {
				pins = "gpio27";
				function = "gpio";
			};

			config {
				pins = "gpio27";
				function = "qdss_tracectl_a";
				drive-strength = <16>;
				bias-disable;
			};
		};

		seta_2: seta_2 {
			mux {
				pins = "gpio28";
				function = "qdss_tracectl_a";
			};

			config {
				pins = "gpio28";
				drive-strength = <16>;
				bias-disable;
			};
		};

		seta_3: seta_3 {
			mux {
				pins = "gpio53";
				function = "qdss_tracedata_a";
			};

			config {
				pins = "gpio53";
				drive-strength = <16>;
				bias-disable;
			};
		};

		seta_4: seta_4 {
			mux {
				pins = "gpio54";
				function = "qdss_tracedata_a";
			};

			config {
				pins = "gpio54";
				drive-strength = <16>;
				bias-disable;
			};
		};

		seta_5: seta_5 {
			mux {
				pins = "gpio63";
				function = "qdss_tracedata_a";
			};

			config {
				pins = "gpio63";
				drive-strength = <16>;
				bias-disable;
			};
		};

		seta_6: seta_6 {
			mux {
				pins = "gpio64";
				function = "qdss_tracedata_a";
			};

			config {
				pins = "gpio64";
				drive-strength = <16>;
				bias-disable;
			};
		};

		seta_7: seta_7 {
			mux {
				pins = "gpio65";
				function = "qdss_tracedata_a";
			};

			config {
				pins = "gpio65";
				drive-strength = <16>;
				bias-disable;
			};
		};

		seta_8: seta_8 {
			mux {
				pins = "gpio66";
				function = "qdss_tracedata_a";
			};

			config {
				pins = "gpio66";
				drive-strength = <16>;
				bias-disable;
			};
		};

		seta_9: seta_9 {
			mux {
				pins = "gpio67";
				function = "qdss_tracedata_a";
			};

			config {
				pins = "gpio67";
				drive-strength = <16>;
				bias-disable;
			};
		};

		seta_10: seta_10 {
			mux {
				pins = "gpio74";
				function = "qdss_tracedata_a";
			};

			config {
				pins = "gpio74";
				drive-strength = <16>;
				bias-disable;
			};
		};

		seta_11: seta_11 {
			mux {
				pins = "gpio75";
				function = "qdss_tracedata_a";
			};

			config {
				pins = "gpio75";
				drive-strength = <16>;
				bias-disable;
			};
		};

		seta_12: seta_12 {
			mux {
				pins = "gpio76";
				function = "qdss_tracedata_a";
			};

			config {
				pins = "gpio76";
				drive-strength = <16>;
				bias-disable;
			};
		};
/*
		seta_13: seta_13 {
			mux {
				pins = "gpio77";
				function = "qdss_tracedata_a";
			};

			config {
				pins = "gpio77";
				drive-strength = <16>;
				bias-disable;
			};
		};

		seta_14: seta_14 {
			mux {
				pins = "gpio85";
				function = "qdss_tracedata_a";
			};

			config {
				pins = "gpio85";
				drive-strength = <16>;
				bias-disable;
			};
		};

		seta_15: seta_15 {
			mux {
				pins = "gpio86";
				function = "qdss_tracedata_a";
			};

			config {
				pins = "gpio86";
				drive-strength = <16>;
				bias-disable;
			};
		};

		seta_16: seta_16 {
			mux {
				pins = "gpio87";
				function = "qdss_tracedata_a";
			};

			config {
				pins = "gpio87";
				drive-strength = <16>;
				bias-disable;
			};
		};

		seta_17: seta_17 {
			mux {
				pins = "gpio89";
				function = "qdss_tracedata_a";
			};

			config {
				pins = "gpio89";
				drive-strength = <16>;
				bias-disable;
			};
		};
*/
		seta_18: seta_18 {
			mux {
				pins = "gpio90";
				function = "qdss_tracedata_a";
			};

			config {
				pins = "gpio90";
				drive-strength = <16>;
				bias-disable;
			};
		};

		setb_1: setb_1 {
			mux {
				pins = "gpio13";
				function = "qdss_tracedata_b";
			};

			config {
				pins = "gpio13";
				drive-strength = <16>;
				bias-disable;
			};
		};

		setb_2: setb_2 {
			mux {
				pins = "gpio14";
				function = "qdss_tracedata_b";
			};

			config {
				pins = "gpio14";
				drive-strength = <16>;
				bias-disable;
			};
		};

		setb_3: setb_3 {
			mux {
				pins = "gpio15";
				function = "qdss_tracedata_b";
			};

			config {
				pins = "gpio15";
				drive-strength = <16>;
				bias-disable;
			};
		};

		setb_4: setb_4 {
			mux {
				pins = "gpio16";
				function = "qdss_tracedata_b";
			};

			config {
				pins = "gpio16";
				drive-strength = <16>;
				bias-disable;
			};
		};

		setb_5: setb_5 {
			mux {
				pins = "gpio17";
				function = "qdss_tracedata_b";
			};

			config {
				pins = "gpio17";
				drive-strength = <16>;
				bias-disable;
			};
		};

		setb_6: setb_6 {
			mux {
				pins = "gpio18";
				function = "qdss_tracedata_b";
			};

			config {
				pins = "gpio18";
				drive-strength = <16>;
				bias-disable;
			};
		};

		setb_7: setb_7 {
			mux {
				pins = "gpio19";
				function = "qdss_tracedata_b";
			};

			config {
				pins = "gpio19";
				drive-strength = <16>;
				bias-disable;
			};
		};

		setb_8: setb_8 {
			mux {
				pins = "gpio21";
				function = "qdss_tracedata_b";
			};

			config {
				pins = "gpio21";
				drive-strength = <16>;
				bias-disable;
			};
		};

		setb_9: setb_9 {
			mux {
				pins = "gpio22";
				function = "qdss_tracedata_b";
			};

			config {
				pins = "gpio22";
				drive-strength = <16>;
				bias-disable;
			};
		};

		setb_10: setb_10 {
			mux {
				pins = "gpio23";
				function = "qdss_tracedata_b";
			};

			config {
				pins = "gpio23";
				drive-strength = <16>;
				bias-disable;
			};
		};

		setb_11: setb_11 {
			mux {
				pins = "gpio26";
				function = "qdss_tracedata_b";
			};

			config {
				pins = "gpio26";
				drive-strength = <16>;
				bias-disable;
			};
		};

		setb_12: setb_12 {
			mux {
				pins = "gpio29";
				function = "qdss_tracedata_b";
			};

			config {
				pins = "gpio29";
				drive-strength = <16>;
				bias-disable;
			};
		};

		setb_13: setb_13 {
			mux {
				pins = "gpio57";
				function = "qdss_tracedata_b";
			};

			config {
				pins = "gpio57";
				drive-strength = <16>;
				bias-disable;
			};
		};

		setb_14: setb_14 {
			mux {
				pins = "gpio58";
				function = "qdss_tracedata_b";
			};

			config {
				pins = "gpio58";
				drive-strength = <16>;
				bias-disable;
			};
		};

		setb_15: setb_15 {
			mux {
				pins = "gpio91";
				function = "qdss_traceclk_b";
			};

			config {
				pins = "gpio91";
				drive-strength = <16>;
				bias-disable;
			};
		};

		setb_16: setb_16 {
			mux {
				pins = "gpio92";
				function = "qdss_tracedata_b";
			};

			config {
				pins = "gpio92";
				drive-strength = <16>;
				bias-disable;
			};
		};

		setb_17: setb_17 {
			mux {
				pins = "gpio93";
				function = "qdss_tracedata_b";
			};

			config {
				pins = "gpio93";
				drive-strength = <16>;
				bias-disable;
			};
		};

		setb_18: setb_18 {
			mux {
				pins = "gpio94";
				function = "qdss_tracectl_b";
			};

			config {
				pins = "gpio94";
				drive-strength = <16>;
				bias-disable;
			};
		};

		trigout_a: trigout_a {
			mux {
				pins = "gpio25";
				function = "qdss_cti_trig_out_a";
			};

			config {
				pins = "gpio25";
				drive-strength = <2>;
				bias-disable;
			};
		};

		tsif0_signals_active: tsif0_signals_active {
			tsif1_clk {
				pins = "gpio89"; /* TSIF0 CLK */
				function = "tsif1_clk";
			};
			tsif1_en {
				pins = "gpio90"; /* TSIF0 Enable */
				function = "tsif1_en";
			};
			tsif1_data {
				pins = "gpio91"; /* TSIF0 DATA */
				function = "tsif1_data";
			};
			signals_cfg {
				pins = "gpio89", "gpio90", "gpio91";
				drive_strength = <2>;	/* 2 mA */
				bias-pull-down;		/* pull down */
			};
		};

		/* pin set for HallIC */
		hallic_gpio {
			label = "hallic_gpio";
			hallic_gpio_active: hallic_gpio_active {
				hallic_gpio {
					pins = "gpio124";
					drive-strength = <2>;
					bias-pull-up;
				};
			};
			hallic_gpio_suspend: hallic_gpio_suspend {
				hallic_gpio {
					pins = "gpio124";
					drive-strength = <2>;
					bias-pull-up;
				};
			 };
		};

		/* NFC Start */
		i2c_8 {
			i2c_8_active: i2c_8_active {
				mux {
					pins = "gpio6", "gpio7";
					function = "blsp_i2c8";
				};

				config {
					pins = "gpio6", "gpio7";
					drive-strength = <2>;
					bias-disable;
				};
			};

			i2c_8_sleep: i2c_8_sleep {
				mux {
					pins = "gpio6", "gpio7";
					function = "blsp_i2c8";
				};

				config {
					pins = "gpio6", "gpio7";
					drive-strength = <2>;
					bias-pull-up;
				};
			};

		};

		pmx_rd_nfc_int{
			label = "pmx_nfc_int";
			nfc_int_active: active {
				pins = "gpio9";
				drive-strength = <6>;
				bias-disable;
			};
			nfc_int_suspend: suspend {
				pins = "gpio9";
				drive-strength = <6>;
				bias-disable;
			};
		};

		pmx_nfc_reset{
			label = "pmx_nfc_disable";
			nfc_disable_active: active {
				pins = "gpio45";
				drive-strength = <6>;
				bias-disable;
			};

			nfc_disable_suspend: suspend {
				pins = "gpio45";
				drive-strength = <6>;
				bias-disable;
			};
		};

		pmx_nfc_mode{
			label = "pmx_nfc_mode";

			nfc_mode_active: active {
				pins = "gpio12";
				drive-strength = <6>;
				bias-disable;
			};

			nfc_mode_suspend: suspend {
				pins = "gpio12";
				drive-strength = <6>;
				 bias-disable;
			};
		};

		pmx_nfc_hvdd_rev_0{
			label = "pmx_nfc_hvdd_rev_0";

			nfc_hvdd_rev_0_active: active {
				pins = "gpio61";
				drive-strength = <6>;
				bias-disable;
			};

			nfc_hvdd_rev_0_suspend: suspend {
				pins = "gpio61";
				drive-strength = <6>;
				bias-disable;
			};
		};

		pmx_nfc_hvdd_rev_a{
			label = "pmx_nfc_hvdd_rev_a";

			nfc_hvdd_rev_a_active: active {
				pins = "gpio82";
				drive-strength = <6>;
				bias-disable;
			};

			nfc_hvdd_rev_a_suspend: suspend {
				pins = "gpio82";
				drive-strength = <6>;
				bias-disable;
			};
		};

		pmx_nfc_wake{
			label = "pmx_nfc_wake";

			nfc_wake_active: active {
				pins = "gpio12";
				drive-strength = <6>;
				bias-pull-up;
			};
			nfc_wake_suspend: suspend {
				pins = "gpio12";
				drive-strength = <6>;
				bias-disable;
			};
		};
		/* NFC End */

		/* pin set for IrRC */
		irrc_uart {
			label = "irrc_uart";

			irrc_uart_active: irrc_uart_active {
				mux {
					pins = "gpio25", "gpio26";
					function = "blsp_uart6";
				};

				config {
					pins = "gpio25", "gpio26";
					drive-strength = <2>;
					bias-disable;
				};
			};

			irrc_uart_sleep: irrc_uart_sleep {
				mux {
					pins = "gpio25", "gpio26";
					function = "blsp_uart6";
				};

				config {
					pins = "gpio25", "gpio26";
					drive-strength = <2>;
					bias-disable;
				};
			};
		};

		irrc_rst {
			label = "irrc_rst";

			irrc_rst_active: irrc_rst_active {
				pins = "gpio73";
				drive-strength = <2>;
				bias-disable;
			};

			irrc_rst_sleep: irrc_rst_sleep {
				pins = "gpio73";
				drive-strength = <2>;
				bias-disable;
			};
		};

		/* Relevant friends pin */
		friends_detect_pin {
			friends_detect_active: friends_detect_active {
				mux {
					pins = "gpio132";
					function = "gpio";
				};

				config {
					pins = "gpio132";
					drive-strength = <6>;
					bias-disable;
				};
			};

			friends_detect_sleep: friends_detect_sleep {
				mux {
					pins = "gpio132";
					function = "gpio";
				};

				config {
					pins = "gpio132";
					drive-strength = <2>;
					bias-disable;
				};
			};
		};

		friends_int_pin {
			friends_int_active: friends_int_active {
				mux {
					pins = "gpio119";
					function = "gpio";
				};

				config {
					pins = "gpio119";
					drive-strength = <10>;
					bias-disable;
				};
			};

			friends_int_sleep: friends_int_sleep {
				mux {
					pins = "gpio119";
					function = "gpio";
				};

				config {
					pins = "gpio119";
					drive-strength = <2>;
					bias-disable;
				};
			};
		};

		friends_id_pin {
			friends_id_active: friends_id_active {
				mux {
					pins = "gpio90";
					function = "gpio";
				};

				config {
					pins = "gpio90";
					drive-strength = <10>;
					bias-disable;
				};
			};

			friends_id_sleep: friends_id_sleep {
				mux {
					pins = "gpio90";
					function = "gpio";
				};

				config {
					pins = "gpio90";
					drive-strength = <2>;
					bias-disable;
				};
			};
		};
	};
};
